AUTOSAR XML (schema 4-0-3)
standard types defined: Boolean, UInt32
package /AUTOSAR_Platform/DataConstrs
  range DC_Boolean: raw 0..1
package /PATAC/Facility/DataTypes/Implementation
  compu method COMPU_Boolean: 0=FALSE, 1=TRUE
  unit NoUnit: factor-si-to-unit=1, offset-si-to-unit=0
package /PATAC/MSM/ComponentTypes
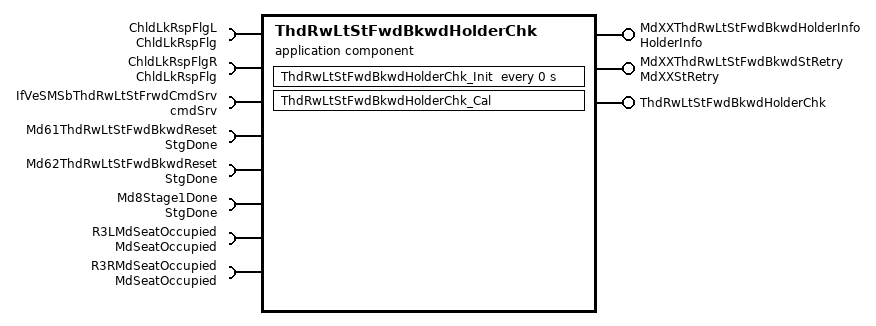
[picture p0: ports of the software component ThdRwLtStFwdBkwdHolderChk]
  application sw component type ThdRwLtStFwdBkwdHolderChk
    provide port MdXXThdRwLtStFwdBkwdHolderInfo: nonqueued-sender-com-spec{data-element=HolderInfo/Val, init-value=0}, provided-interface=HolderInfo
    provide port MdXXThdRwLtStFwdBkwdStRetry: nonqueued-sender-com-spec{data-element=MdXXStRetry/Val, init-value=0}, provided-interface=MdXXStRetry
    provide port ThdRwLtStFwdBkwdHolderChk: server-com-spec{operation=Cal, queue-length=1}, provided-interface=ThdRwLtStFwdBkwdHolderChk
    8 x require port:
      ChldLkRspFlgL: nonqueued-receiver-com-spec{data-element=ChldLkRspFlg/Val, filter=data-filter-type=ALWAYS, init-value=0}, required-interface=ChldLkRspFlg
      ChldLkRspFlgR: nonqueued-receiver-com-spec{data-element=ChldLkRspFlg/Val, filter=data-filter-type=ALWAYS, init-value=0}, required-interface=ChldLkRspFlg
      IfVeSMSbThdRwLtStFrwdCmdSrv: nonqueued-receiver-com-spec{data-element=cmdSrv/Val, filter=data-filter-type=ALWAYS, init-value=1}, required-interface=cmdSrv
      Md61ThdRwLtStFwdBkwdReset: nonqueued-receiver-com-spec{data-element=StgDone/Val, filter=data-filter-type=ALWAYS, init-value=0}, required-interface=StgDone
      Md62ThdRwLtStFwdBkwdReset: nonqueued-receiver-com-spec{data-element=StgDone/Val, filter=data-filter-type=ALWAYS, init-value=0}, required-interface=StgDone
      Md8Stage1Done: nonqueued-receiver-com-spec{data-element=StgDone/Val, filter=data-filter-type=ALWAYS, init-value=0}, required-interface=StgDone
      R3LMdSeatOccupied: nonqueued-receiver-com-spec{data-element=MdSeatOccupied/Val, filter=data-filter-type=ALWAYS, init-value=0}, required-interface=MdSeatOccupied
      R3RMdSeatOccupied: nonqueued-receiver-com-spec{data-element=MdSeatOccupied/Val, filter=data-filter-type=ALWAYS, init-value=0}, required-interface=MdSeatOccupied
    behavior ThdRwLtStFwdBkwdHolderChk_InternalBehavior
      operation invoked event OIT_ThdRwLtStFwdBkwdHolderChk_Cal_ThdRwLtStFwdBkwdHolderChk_Cal: start-on-event=ThdRwLtStFwdBkwdHolderChk_Cal, operation=ThdRwLtStFwdBkwdHolderChk.Cal
      timing event ThdRwLtStFwdBkwdHolderChk_InitEvent: start-on-event=ThdRwLtStFwdBkwdHolderChk_Init, period=0
      runnable ThdRwLtStFwdBkwdHolderChk_Cal
        data-receive-point-by-arguments:
          8 x access:
            REC_ChldLkRspFlgL_Val: accessed-variable=ChldLkRspFlgL.Val
            REC_ChldLkRspFlgR_Val: accessed-variable=ChldLkRspFlgR.Val
            REC_IfVeSMSbThdRwLtStFrwdCmdSrv_Val: accessed-variable=IfVeSMSbThdRwLtStFrwdCmdSrv.Val
            REC_Md61ThdRwLtStFwdBkwdReset_Val: accessed-variable=Md61ThdRwLtStFwdBkwdReset.Val
            REC_Md62ThdRwLtStFwdBkwdReset_Val: accessed-variable=Md62ThdRwLtStFwdBkwdReset.Val
            REC_Md8Stage1Done_Val: accessed-variable=Md8Stage1Done.Val
            REC_R3LMdSeatOccupied_Val: accessed-variable=R3LMdSeatOccupied.Val
            REC_R3RMdSeatOccupied_Val: accessed-variable=R3RMdSeatOccupied.Val
        data-send-points:
          access SEND_MdXXThdRwLtStFwdBkwdHolderInfo_Val: accessed-variable=MdXXThdRwLtStFwdBkwdHolderInfo.Val
          access SEND_MdXXThdRwLtStFwdBkwdStRetry_Val: accessed-variable=MdXXThdRwLtStFwdBkwdStRetry.Val
      runnable ThdRwLtStFwdBkwdHolderChk_Init
  swc implementation ThdRwLtStFwdBkwdHolderChk_Implementation: behavior=ThdRwLtStFwdBkwdHolderChk_InternalBehavior
    code-descriptors:
      code Default: artifact-descriptors=autosar-engineering-object={short-label=Default, category=SWSRC}
package /PATAC/MSM/Intervene/PortInterfaces
  sender receiver interface cmdSrv: invalidation-policy{data-element=cmdSrv/Val, handle-invalid=DONT-INVALIDATE}
    data Val: type=Boolean
package /PATAC/MSM/ModeAdjust/PortInterface
  client server interface ThdRwLtStFwdBkwdHolderChk
    operation Cal
  5 x sender receiver interface:
    ChldLkRspFlg: invalidation-policy{data-element=ChldLkRspFlg/Val, handle-invalid=DONT-INVALIDATE}
      data Val: type=Boolean
    HolderInfo: invalidation-policy{data-element=HolderInfo/Val, handle-invalid=DONT-INVALIDATE}
      data Val: type=UInt32
    MdSeatOccupied: invalidation-policy{data-element=MdSeatOccupied/Val, handle-invalid=DONT-INVALIDATE}
      data Val: type=Boolean
    MdXXStRetry: invalidation-policy{data-element=MdXXStRetry/Val, handle-invalid=DONT-INVALIDATE}
      data Val: type=UInt32
    StgDone: invalidation-policy{data-element=StgDone/Val, handle-invalid=DONT-INVALIDATE}
      data Val: type=Boolean
